AUTOSAR XML (schema 4-0-3)
package /ComponentTypes
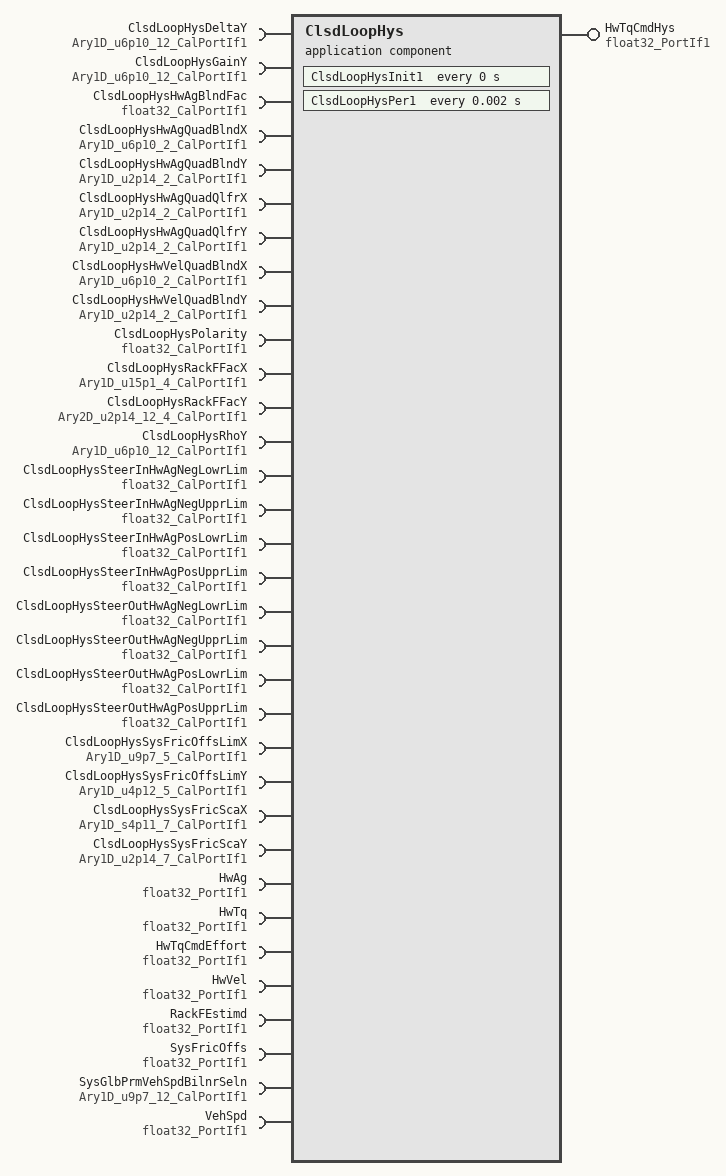
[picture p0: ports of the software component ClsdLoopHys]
  application sw component type ClsdLoopHys
    provide port HwTqCmdHys: nonqueued-sender-com-spec{data-element=Val, init-value=0}, provided-interface=float32_PortIf1
    33 x require port:
      ClsdLoopHysDeltaY: parameter-require-com-spec{init-value=[205, 205, 256, 307, 512, 512, 512, 512, 512, 512, 512, 512], parameter=Ary1D}, required-interface=Ary1D_u6p10_12_CalPortIf1
      ClsdLoopHysGainY: parameter-require-com-spec{init-value=[205, 205, 205, 102, 102, 51, 51, 51, 51, 51, 51, 51], parameter=Ary1D}, required-interface=Ary1D_u6p10_12_CalPortIf1
      ClsdLoopHysHwAgBlndFac: parameter-require-com-spec{init-value=0.2, parameter=Val}, required-interface=float32_CalPortIf1
      ClsdLoopHysHwAgQuadBlndX: parameter-require-com-spec{init-value=[0, 102], parameter=Ary1D}, required-interface=Ary1D_u6p10_2_CalPortIf1
      ClsdLoopHysHwAgQuadBlndY: parameter-require-com-spec{init-value=[0, 16384], parameter=Ary1D}, required-interface=Ary1D_u2p14_2_CalPortIf1
      ClsdLoopHysHwAgQuadQlfrX: parameter-require-com-spec{init-value=[0, 16384], parameter=Ary1D}, required-interface=Ary1D_u2p14_2_CalPortIf1
      ClsdLoopHysHwAgQuadQlfrY: parameter-require-com-spec{init-value=[0, 16384], parameter=Ary1D}, required-interface=Ary1D_u2p14_2_CalPortIf1
      ClsdLoopHysHwVelQuadBlndX: parameter-require-com-spec{init-value=[0, 1024], parameter=Ary1D}, required-interface=Ary1D_u6p10_2_CalPortIf1
      ClsdLoopHysHwVelQuadBlndY: parameter-require-com-spec{init-value=[0, 16384], parameter=Ary1D}, required-interface=Ary1D_u2p14_2_CalPortIf1
      ClsdLoopHysPolarity: parameter-require-com-spec{init-value=1, parameter=Val}, required-interface=float32_CalPortIf1
      ClsdLoopHysRackFFacX: parameter-require-com-spec{init-value=[0, 2000, 10000, 18000], parameter=Ary1D}, required-interface=Ary1D_u15p1_4_CalPortIf1
      ClsdLoopHysRackFFacY: parameter-require-com-spec{init-value=12 x [164, 164, 164, 164], parameter=Ary2D}, required-interface=Ary2D_u2p14_12_4_CalPortIf1
      ClsdLoopHysRhoY: parameter-require-com-spec{init-value=[10240, 10240, 5120, 5120, 3072, 3072, 2560, 2560, 2560, 2560, 2560, 0], parameter=Ary1D}, required-interface=Ary1D_u6p10_12_CalPortIf1
      ClsdLoopHysSteerInHwAgNegLowrLim: parameter-require-com-spec{init-value=-1, parameter=Val}, required-interface=float32_CalPortIf1
      ClsdLoopHysSteerInHwAgNegUpprLim: parameter-require-com-spec{init-value=1, parameter=Val}, required-interface=float32_CalPortIf1
      ClsdLoopHysSteerInHwAgPosLowrLim: parameter-require-com-spec{init-value=-1, parameter=Val}, required-interface=float32_CalPortIf1
      ClsdLoopHysSteerInHwAgPosUpprLim: parameter-require-com-spec{init-value=1, parameter=Val}, required-interface=float32_CalPortIf1
      ClsdLoopHysSteerOutHwAgNegLowrLim: parameter-require-com-spec{init-value=-0.1, parameter=Val}, required-interface=float32_CalPortIf1
      ClsdLoopHysSteerOutHwAgNegUpprLim: parameter-require-com-spec{init-value=0.1, parameter=Val}, required-interface=float32_CalPortIf1
      ClsdLoopHysSteerOutHwAgPosLowrLim: parameter-require-com-spec{init-value=-0.1, parameter=Val}, required-interface=float32_CalPortIf1
      ClsdLoopHysSteerOutHwAgPosUpprLim: parameter-require-com-spec{init-value=0.1, parameter=Val}, required-interface=float32_CalPortIf1
      ClsdLoopHysSysFricOffsLimX: parameter-require-com-spec{init-value=[0, 1280, 5120, 10240, 25600], parameter=Ary1D}, required-interface=Ary1D_u9p7_5_CalPortIf1
      ClsdLoopHysSysFricOffsLimY: parameter-require-com-spec{init-value=[20480, 20480, 16384, 4096, 0], parameter=Ary1D}, required-interface=Ary1D_u4p12_5_CalPortIf1
      ClsdLoopHysSysFricScaX: parameter-require-com-spec{init-value=[-10240, -8192, -4096, 0, 4096, 8192, 10240], parameter=Ary1D}, required-interface=Ary1D_s4p11_7_CalPortIf1
      ClsdLoopHysSysFricScaY: parameter-require-com-spec{init-value=[19661, 19661, 18022, 16384, 14746, 13107, 13107], parameter=Ary1D}, required-interface=Ary1D_u2p14_7_CalPortIf1
      HwAg: nonqueued-receiver-com-spec{data-element=Val, filter=data-filter-type=ALWAYS, init-value=0}, required-interface=float32_PortIf1
      HwTq: nonqueued-receiver-com-spec{data-element=Val, filter=data-filter-type=ALWAYS, init-value=0}, required-interface=float32_PortIf1
      HwTqCmdEffort: nonqueued-receiver-com-spec{data-element=Val, filter=data-filter-type=ALWAYS, init-value=0}, required-interface=float32_PortIf1
      HwVel: nonqueued-receiver-com-spec{data-element=Val, filter=data-filter-type=ALWAYS, init-value=0}, required-interface=float32_PortIf1
      RackFEstimd: nonqueued-receiver-com-spec{data-element=Val, filter=data-filter-type=ALWAYS, init-value=0}, required-interface=float32_PortIf1
      SysFricOffs: nonqueued-receiver-com-spec{data-element=Val, filter=data-filter-type=ALWAYS, init-value=0}, required-interface=float32_PortIf1
      SysGlbPrmVehSpdBilnrSeln: parameter-require-com-spec{init-value=[0, 640, 1920, 3840, 7680, 10240, 12800, 15360, 19200, 23040, 25600, 28160], parameter=Ary1D}, required-interface=Ary1D_u9p7_12_CalPortIf1
      VehSpd: nonqueued-receiver-com-spec{data-element=Val, filter=data-filter-type=ALWAYS, init-value=0}, required-interface=float32_PortIf1
    behavior ClsdLoopHys_InternalBehavior
      ar-typed-per-instance-memorys:
        data IntgtrSt: sw-calibration-access=READ-ONLY, type=float32
      timing event ClsdLoopHys_InitEvent: start-on-event=ClsdLoopHysInit1, period=0
      timing event TMT_ClsdLoopHysPer1: start-on-event=ClsdLoopHysPer1, period=0.002
      runnable ClsdLoopHysInit1
      runnable ClsdLoopHysPer1
        data-receive-point-by-arguments:
          7 x access:
            REC_HwAg_Val: accessed-variable=HwAg.Val
            REC_HwTq_Val: accessed-variable=HwTq.Val
            REC_HwTqCmdEffort_Val: accessed-variable=HwTqCmdEffort.Val
            REC_HwVel_Val: accessed-variable=HwVel.Val
            REC_RackFEstimd_Val: accessed-variable=RackFEstimd.Val
            REC_SysFricOffs_Val: accessed-variable=SysFricOffs.Val
            REC_VehSpd_Val: accessed-variable=VehSpd.Val
        data-send-points:
          access SEND_HwTqCmdHys_Val: accessed-variable=HwTqCmdHys.Val
  swc implementation ClsdLoopHys_Implementation: behavior=ClsdLoopHys_InternalBehavior
    code-descriptors:
      code Default: artifact-descriptors=autosar-engineering-object={short-label=Default, category=SWSRC}
